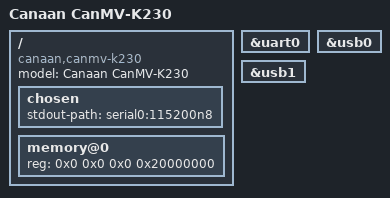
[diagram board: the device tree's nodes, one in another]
// SPDX-License-Identifier: GPL-2.0 OR MIT
/*
 * Copyright (C) 2024 Yangyu Chen <cyy@cyyself.name>
 * Copyright (C) 2024 Junhui Liu <liujh2818@outlook.com>
 */

/dts-v1/;
#include "k230.dtsi"

/ {
	model = "Canaan CanMV-K230";
	compatible = "canaan,canmv-k230", "canaan,kendryte-k230";

	chosen {
		stdout-path = "serial0:115200n8";
	};

	memory@0 {
		device_type = "memory";
		reg = <0x0 0x0 0x0 0x20000000>;
	};
};

&uart0 {
	status = "okay";
};

/* USB-C port */
&usb0 {
	status = "okay";
};

/* Onboard RTL8152 */
&usb1 {
	status = "okay";
};
